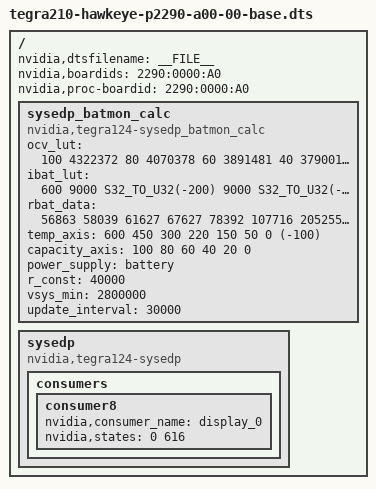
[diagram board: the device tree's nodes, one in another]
/*
 * tegra210-hawkeye-p2290-a00-00-base.dts: Hawkeye P2290 A00 board.
 *
 * Copyright (c) 2014-2015, NVIDIA CORPORATION.  All rights reserved.
 *
 * This program is free software; you can redistribute it and/or modify
 * it under the terms of the GNU General Public License as published by
 * the Free Software Foundation; version 2 of the License.
 *
 * This program is distributed in the hope that it will be useful, but WITHOUT
 * ANY WARRANTY; without even the implied warranty of MERCHANTABILITY or
 * FITNESS FOR A PARTICULAR PURPOSE.  See the GNU General Public License for
 * more details.
 */

#include "tegra210-hawkeye-p2290-common.dtsi"
#include "tegra210-platforms/tegra210-sysedp-670d.dtsi"

/ {
	nvidia,dtsfilename = __FILE__;
	nvidia,boardids = "2290:0000:A0";
	nvidia,proc-boardid = "2290:0000:A0";

	sysedp_batmon_calc {
		compatible = "nvidia,tegra124-sysedp_batmon_calc";
		ocv_lut = <
			100 4322372
			80  4070378
			60  3891481
			40  3790013
			20  3730816
			0   3484195
		>;
		ibat_lut = <
			600 9000
			S32_TO_U32(-200) 9000
			S32_TO_U32(-300) 0
		>;
		rbat_data = <
		/*	600	450	300	220	150	50	0	-100   deci Celsius */
			56863   58039   61627   67627   78392   107716  205255  205255  /* 100% SOC */
			56863   58039   61627   67608   78392   130762  206304  206304  /* 80% SOC  */
			56863   57451   61647   68824   80784   136468  207774  207774  /* 60% SOC  */
			56088   59235   62824   70608   84980   154188  228354  228354  /* 40% SOC  */
			56863   59235   66431   76000   97549   181734  248747  248747  /* 20% SOC  */
			58824   60431   74196   99333   134647  197775  259098  259098  /* 0% SOC   */
		>;
		temp_axis = <600 450 300 220 150 50 0 (-100)>;
		capacity_axis = <100 80 60 40 20 0>;
		power_supply = "battery";
		r_const = <40000>;
		vsys_min = <2800000>;
		update_interval = <30000>;
	};

	sysedp {
		compatible = "nvidia,tegra124-sysedp";
		consumers {
			consumer8 {
				/* non-shipping ST8 AUO 8" display */
				nvidia,consumer_name = "display_0";
				nvidia,states = <0 616>;
			};
		};
	};
};
